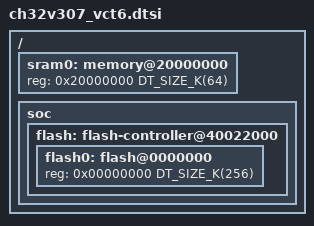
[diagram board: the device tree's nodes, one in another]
/*
 * Copyright (c) 2021 Nanjing Qinheng Microelectronics Co., Ltd.
 *
 * SPDX-License-Identifier: Apache-2.0
 */
 
#include <mem.h>
#include <wch/ch32v307.dtsi>

/ {
	sram0: memory@20000000 {
		reg = <0x20000000 DT_SIZE_K(64)>;
	};	
	soc {
		flash: flash-controller@40022000 {
			flash0: flash@0000000 {
				reg = <0x00000000 DT_SIZE_K(256)>;
			};
		};
	};
};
